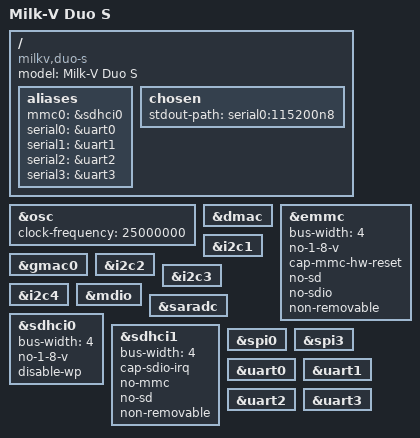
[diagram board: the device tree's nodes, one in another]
// SPDX-License-Identifier: (GPL-2.0 OR MIT)

/dts-v1/;

#include <dt-bindings/pinctrl/pinctrl-cv1812h.h>
#include "cv1812h.dtsi"

/ {
	model = "Milk-V Duo S";
	compatible = "milkv,duo-s", "sophgo,cv1812h";

	aliases {
		mmc0 = &sdhci0;
		serial0 = &uart0;
		serial1 = &uart1;
		serial2 = &uart2;
		serial3 = &uart3;
	};

	chosen {
		stdout-path = "serial0:115200n8";
	};
};

&osc {
	clock-frequency = <25000000>;
};

&dmac {
	status = "okay";
};

&emmc {
	bus-width = <4>;
	no-1-8-v;
	cap-mmc-hw-reset;
	no-sd;
	no-sdio;
	non-removable;
	status = "okay";
};

&gmac0 {
	status = "okay";
};

&i2c1 {
	status = "okay";
};

&i2c2 {
	status = "okay";
};

&i2c3 {
	status = "okay";
};

&i2c4 {
	status = "okay";
};

&mdio {
	status = "okay";
};

&saradc {
	status = "okay";
};

&sdhci0 {
	bus-width = <4>;
	no-1-8-v;
	disable-wp;
	status = "okay";
};

&sdhci1 {
	bus-width = <4>;
	cap-sdio-irq;
	no-mmc;
	no-sd;
	non-removable;
	status = "okay";
};

&spi0 {
	status = "okay";
};

&spi3 {
	status = "okay";
};

&uart0 {
	status = "okay";
};

&uart1 {
	status = "okay";
};

&uart2 {
	status = "okay";
};

&uart3 {
	status = "okay";
};

